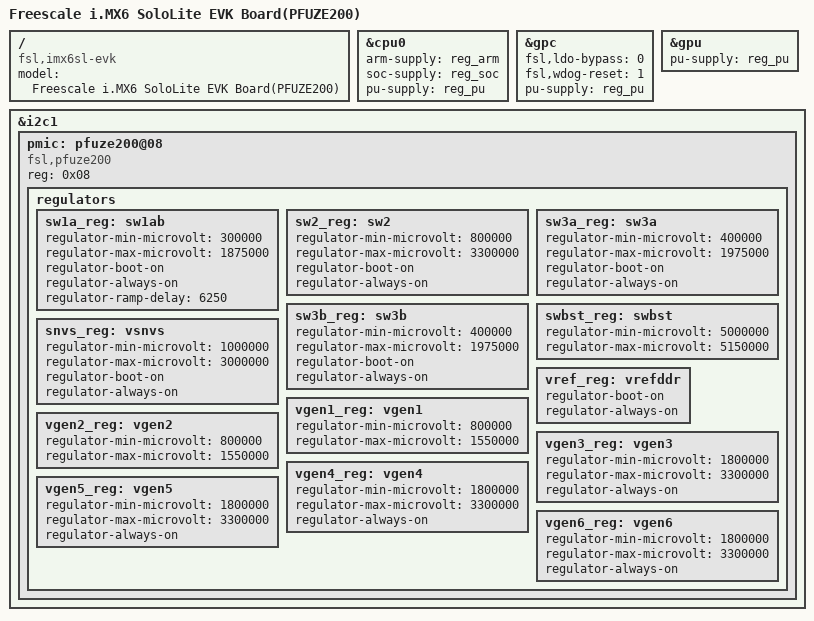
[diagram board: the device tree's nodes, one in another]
/*
 * Copyright (C) 2013-2014 Freescale Semiconductor, Inc.
 *
 * This program is free software; you can redistribute it and/or modify
 * it under the terms of the GNU General Public License version 2 as
 * published by the Free Software Foundation.
 */

/dts-v1/;

#include "imx6sl.dtsi"
#include "imx6sl-evk-common.dtsi"

/ {
	model = "Freescale i.MX6 SoloLite EVK Board(PFUZE200)";
	compatible = "fsl,imx6sl-evk", "fsl,imx6sl";
};

&cpu0 {
	arm-supply = <&reg_arm>;
	soc-supply = <&reg_soc>;
	pu-supply = <&reg_pu>; /* use pu_dummy if VDDSOC share with VDDPU */
};

&gpc {
	fsl,ldo-bypass = <0>; /* use ldo-bypass, u-boot will check it and configure */
	fsl,wdog-reset = <1>; /* watchdog select of reset source */
	pu-supply = <&reg_pu>; /* ldo-bypass:use pu_dummy if VDDSOC share with VDDPU */
};

&gpu {
	pu-supply = <&reg_pu>; /* ldo-bypass:use pu_dummy if VDDSOC share with VDDPU */
};

&i2c1 {
	pmic: pfuze200@08 {
		compatible = "fsl,pfuze200";
		reg = <0x08>;

		regulators {
			sw1a_reg: sw1ab {
				regulator-min-microvolt = <300000>;
				regulator-max-microvolt = <1875000>;
				regulator-boot-on;
				regulator-always-on;
				regulator-ramp-delay = <6250>;
			};

			sw2_reg: sw2 {
				regulator-min-microvolt = <800000>;
				regulator-max-microvolt = <3300000>;
				regulator-boot-on;
				regulator-always-on;
			};

			sw3a_reg: sw3a {
				regulator-min-microvolt = <400000>;
				regulator-max-microvolt = <1975000>;
				regulator-boot-on;
				regulator-always-on;
			};

			sw3b_reg: sw3b {
				regulator-min-microvolt = <400000>;
				regulator-max-microvolt = <1975000>;
				regulator-boot-on;
				regulator-always-on;
			};

			swbst_reg: swbst {
				regulator-min-microvolt = <5000000>;
				regulator-max-microvolt = <5150000>;
			};

			snvs_reg: vsnvs {
				regulator-min-microvolt = <1000000>;
				regulator-max-microvolt = <3000000>;
				regulator-boot-on;
				regulator-always-on;
			};

			vref_reg: vrefddr {
				regulator-boot-on;
				regulator-always-on;
			};

			vgen1_reg: vgen1 {
				regulator-min-microvolt = <800000>;
				regulator-max-microvolt = <1550000>;
			};

			vgen2_reg: vgen2 {
				regulator-min-microvolt = <800000>;
				regulator-max-microvolt = <1550000>;
			};

			vgen3_reg: vgen3 {
				regulator-min-microvolt = <1800000>;
				regulator-max-microvolt = <3300000>;
				regulator-always-on;
			};

			vgen4_reg: vgen4 {
				regulator-min-microvolt = <1800000>;
				regulator-max-microvolt = <3300000>;
				regulator-always-on;
			};

			vgen5_reg: vgen5 {
				regulator-min-microvolt = <1800000>;
				regulator-max-microvolt = <3300000>;
				regulator-always-on;
			};

			vgen6_reg: vgen6 {
				regulator-min-microvolt = <1800000>;
				regulator-max-microvolt = <3300000>;
				regulator-always-on;
			};
		};
	};
};
